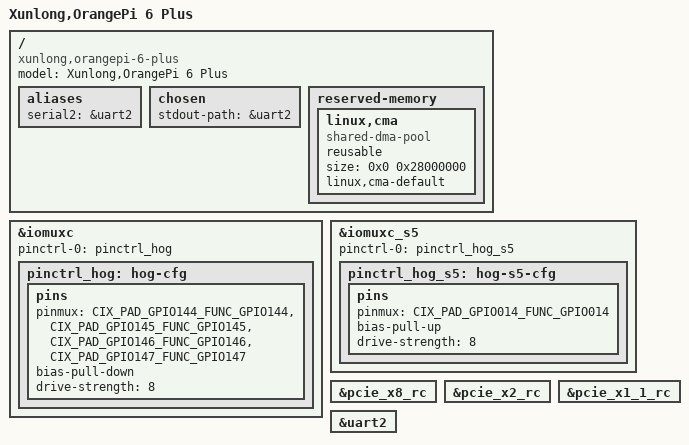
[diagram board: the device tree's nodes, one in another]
// SPDX-License-Identifier: BSD-3-Clause
/*
 * Copyright 2025 Cix Technology Group Co., Ltd.
 *
 */

/dts-v1/;

#include "sky1.dtsi"
#include "sky1-pinfunc.h"

/ {
	model = "Xunlong,OrangePi 6 Plus";
	compatible = "xunlong,orangepi-6-plus", "cix,sky1";

	aliases {
		serial2 = &uart2;
	};

	chosen {
		stdout-path = &uart2;
	};

	reserved-memory {
		#address-cells = <2>;
		#size-cells = <2>;
		ranges;

		linux,cma {
			compatible = "shared-dma-pool";
			reusable;
			size = <0x0 0x28000000>;
			linux,cma-default;
		};
	};

};

&iomuxc {
	pinctrl-names = "default";
	pinctrl-0 = <&pinctrl_hog>;

	pinctrl_hog: hog-cfg {
		pins {
			pinmux = <CIX_PAD_GPIO144_FUNC_GPIO144>,
				<CIX_PAD_GPIO145_FUNC_GPIO145>,
				<CIX_PAD_GPIO146_FUNC_GPIO146>,
				<CIX_PAD_GPIO147_FUNC_GPIO147>;
			bias-pull-down;
			drive-strength = <8>;
		};
	};
};

&iomuxc_s5 {
	pinctrl-names = "default";
	pinctrl-0 = <&pinctrl_hog_s5>;

	pinctrl_hog_s5: hog-s5-cfg {
		pins {
			pinmux = <CIX_PAD_GPIO014_FUNC_GPIO014>;
			bias-pull-up;
			drive-strength = <8>;

		};
	};
};

&pcie_x8_rc {
	status = "okay";
};

&pcie_x2_rc {
	status = "okay";
};

&pcie_x1_1_rc {
	status = "okay";
};

&uart2 {
	status = "okay";
};
